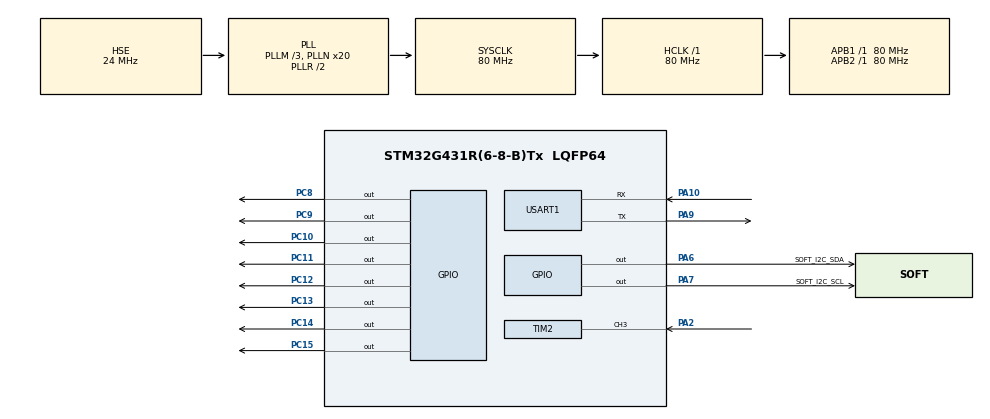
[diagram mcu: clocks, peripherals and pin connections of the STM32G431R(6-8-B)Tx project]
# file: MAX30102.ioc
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Mcu.Family=STM32G4
Mcu.Name=STM32G431R(6-8-B)Tx
Mcu.Package=LQFP64
NVIC.PriorityGroup=NVIC_PRIORITYGROUP_4
NVIC.TIM2_IRQn=true\:0\:0\:false\:false\:true\:true\:true\:true
PA10.Mode=Asynchronous
PA10.Signal=USART1_RX
PA13.Mode=Serial_Wire
PA13.Signal=SYS_JTMS-SWDIO
PA14.Mode=Serial_Wire
PA14.Signal=SYS_JTCK-SWCLK
PA2.Signal=S_TIM2_CH3
PA6.GPIO_Label=SOFT_I2C_SDA
PA6.Signal=GPIO_Output
PA7.GPIO_Label=SOFT_I2C_SCL
PA7.Signal=GPIO_Output
PA9.Mode=Asynchronous
PA9.Signal=USART1_TX
PC10.Signal=GPIO_Output
PC11.Signal=GPIO_Output
PC12.Signal=GPIO_Output
PC13.Signal=GPIO_Output
PC14-OSC32_IN.Signal=GPIO_Output
PC15-OSC32_OUT.Signal=GPIO_Output
PC8.Signal=GPIO_Output
PC9.Signal=GPIO_Output
PF0-OSC_IN.Mode=HSE-External-Oscillator
PF0-OSC_IN.Signal=RCC_OSC_IN
PF1-OSC_OUT.Mode=HSE-External-Oscillator
PF1-OSC_OUT.Signal=RCC_OSC_OUT
ProjectManager.HeapSize=0x200
ProjectManager.StackSize=0x400
ProjectManager.TargetToolchain=MDK-ARM V5.32
RCC.ADC12Freq_Value=80000000
RCC.AHBFreq_Value=80000000
RCC.APB1Freq_Value=80000000
RCC.APB1TimFreq_Value=80000000
RCC.APB2Freq_Value=80000000
RCC.APB2TimFreq_Value=80000000
RCC.CortexFreq_Value=80000000
RCC.EXTERNAL_CLOCK_VALUE=12288000
RCC.HCLKFreq_Value=80000000
RCC.HSE_VALUE=24000000
RCC.HSI48_VALUE=48000000
RCC.HSI_VALUE=16000000
RCC.LSE_VALUE=32768
RCC.PLLM=RCC_PLLM_DIV3
RCC.PLLN=20
RCC.PLLSourceVirtual=RCC_PLLSOURCE_HSE
RCC.SYSCLKFreq_VALUE=80000000
RCC.SYSCLKSource=RCC_SYSCLKSOURCE_PLLCLK
RCC.USBFreq_Value=80000000
RCC.VCOOutputFreq_Value=160000000
SH.S_TIM2_CH3.0=TIM2_CH3,Input_Capture3_from_TI3
TIM2.Channel-Input_Capture3_from_TI3=TIM_CHANNEL_3
TIM2.Channel-Input_Capture4_from_TI3_63=TIM_CHANNEL_4
TIM2.ICPolarity_CH4=TIM_INPUTCHANNELPOLARITY_FALLING
TIM2.Prescaler=80-1
USART1.VirtualMode-Asynchronous=VM_ASYNC
VP_SYS_VS_DBSignals.Mode=DisableDeadBatterySignals
VP_TIM2_VS_ClockSourceINT.Mode=Internal
VP_TIM2_VS_indirect_ch3.Mode=Input_Capture4_from_TI3_63
board=custom

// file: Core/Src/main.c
/* USER CODE BEGIN Header */
/**
  ******************************************************************************
  * @file           : main.c
  * @brief          : Main program body
  ******************************************************************************
  * @attention
  *
  * Copyright (c) 2025 STMicroelectronics.
  * All rights reserved.
  *
  * This software is licensed under terms that can be found in the LICENSE file
  * in the root directory of this software component.
  * If no LICENSE file comes with this software, it is provided AS-IS.
  *
  ******************************************************************************
  */
/* USER CODE END Header */
#include "main.h"
#include "tim.h"
#include "usart.h"
#include "gpio.h"

/* USER CODE BEGIN PD */
#ifdef __GNUC__
#define PUTCHAR_PROTOTYPE int __io_putchar(int ch)
#else
#define PUTCHAR_PROTOTYPE int fputc(int ch, FILE *f)
#endif

PUTCHAR_PROTOTYPE
{
    HAL_UART_Transmit(&huart1, (uint8_t *)&ch, 1, HAL_MAX_DELAY);
    return ch;
}
// 定义采样点数，减少FFT计算量
#define SAMPLE_SIZE 256
/* USER CODE END PD */

/* USER CODE BEGIN PV */

void HAL_TIM_IC_CaptureCallback(TIM_HandleTypeDef *htim);

/* USER CODE END PV */

void SystemClock_Config(void);

/* USER CODE BEGIN 0 */
/* USER CODE BEGIN 0 */

/* USER CODE END 0 */

int main(void)
{

  /* MCU Configuration--------------------------------------------------------*/

  /* Reset of all peripherals, Initializes the Flash interface and the Systick. */
  HAL_Init();

  /* Configure the system clock */
  SystemClock_Config();

  /* Initialize all configured peripherals */
  MX_GPIO_Init();
  MX_USART1_UART_Init();
  MX_TIM2_Init();
  /* USER CODE BEGIN 2 */
	HAL_GPIO_WritePin(GPIOC, GPIO_PIN_13|GPIO_PIN_14|GPIO_PIN_15|GPIO_PIN_8
                          |GPIO_PIN_9|GPIO_PIN_10|GPIO_PIN_11|GPIO_PIN_12, GPIO_PIN_SET);

	printf("\r\n准备测试\r\n");

// 初始化光敏传感器
// LightSensor_Test();

// 初始化红外反射传感器
//	InfraredTrack_Test();

// 初始化火焰传感器
//	FlameSensor_Test();

// 初始化心率传感器
//	MAX30102_Test();

// 初始化姿态传感器
//  MUP6050_Test();

// 初始化温度传感器
//	DS18B20_Test();

// 初始化温湿度传感器
//	AHT20_Test();

// 初始化气压传感器
//	BMP388_Test();

// 初始化声音传感器
//	SoundSensor_Test();

// 初始化超声波传感器
//	Ultrasonic_Test();

// 初始化压力传感器
//	HX711();

// 初始化人体热释电传感器
//	AS312_Test();

  /* USER CODE END 2 */

  /* Infinite loop */
  /* USER CODE BEGIN WHILE */
  while (1)
  {
//		HAL_Delay(500);
    /* USER CODE END WHILE */

  }
}

void SystemClock_Config(void)
{
  RCC_OscInitTypeDef RCC_OscInitStruct = {0};
  RCC_ClkInitTypeDef RCC_ClkInitStruct = {0};

  /** Configure the main internal regulator output voltage
  */
  HAL_PWREx_ControlVoltageScaling(PWR_REGULATOR_VOLTAGE_SCALE1);

  /** Initializes the RCC Oscillators according to the specified parameters
  * in the RCC_OscInitTypeDef structure.
  */
  RCC_OscInitStruct.OscillatorType = RCC_OSCILLATORTYPE_HSE;
  RCC_OscInitStruct.HSEState = RCC_HSE_ON;
  RCC_OscInitStruct.PLL.PLLState = RCC_PLL_ON;
  RCC_OscInitStruct.PLL.PLLSource = RCC_PLLSOURCE_HSE;
  RCC_OscInitStruct.PLL.PLLM = RCC_PLLM_DIV3;
  RCC_OscInitStruct.PLL.PLLN = 20;
  RCC_OscInitStruct.PLL.PLLP = RCC_PLLP_DIV2;
  RCC_OscInitStruct.PLL.PLLQ = RCC_PLLQ_DIV2;
  RCC_OscInitStruct.PLL.PLLR = RCC_PLLR_DIV2;
  if (HAL_RCC_OscConfig(&RCC_OscInitStruct) != HAL_OK)
  {
    Error_Handler();
  }

  /** Initializes the CPU, AHB and APB buses clocks
  */
  RCC_ClkInitStruct.ClockType = RCC_CLOCKTYPE_HCLK|RCC_CLOCKTYPE_SYSCLK
                              |RCC_CLOCKTYPE_PCLK1|RCC_CLOCKTYPE_PCLK2;
  RCC_ClkInitStruct.SYSCLKSource = RCC_SYSCLKSOURCE_PLLCLK;
  RCC_ClkInitStruct.AHBCLKDivider = RCC_SYSCLK_DIV1;
  RCC_ClkInitStruct.APB1CLKDivider = RCC_HCLK_DIV1;
  RCC_ClkInitStruct.APB2CLKDivider = RCC_HCLK_DIV1;

  if (HAL_RCC_ClockConfig(&RCC_ClkInitStruct, FLASH_LATENCY_2) != HAL_OK)
  {
    Error_Handler();
  }
}

void Error_Handler(void)
{
  __disable_irq();
  while (1)
  {
  }
}
